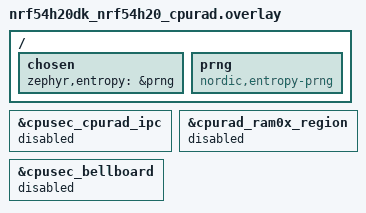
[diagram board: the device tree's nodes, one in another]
/*
 * Copyright (c) 2025 Nordic Semiconductor
 * SPDX-License-Identifier: LicenseRef-Nordic-5-Clause
 */

/* Included because partitions must be moved on both cores App and Rad cores to avoid memory
 * regions overlapping.
 */
#include "nrf54h20dk_nrf54h20-mem-map-move.dtsi"

/* Switch back to the pseudo-random entropy source. */
/ {
	chosen {
		zephyr,entropy = &prng;
	};

	/delete-node/ psa-rng;

	prng: prng {
		compatible = "nordic,entropy-prng";
		status = "okay";
	};

};

/* Disable IPC between cpusec <-> cpurad. */
&cpusec_cpurad_ipc {
	status = "disabled";
};

&cpurad_ram0x_region {
	status = "disabled";
};

&cpusec_bellboard {
	status = "disabled";
};
